# iqn_ail register map
Vendor: Texas Instruments
Registers are 32-bit, read-only, no defined reset value unless marked. A register's access mark holds for its fields unless they carry their own. Offsets are as the file gives them; [hi:lo] are bit positions.

## IQN_AIL (part 5 of 5)
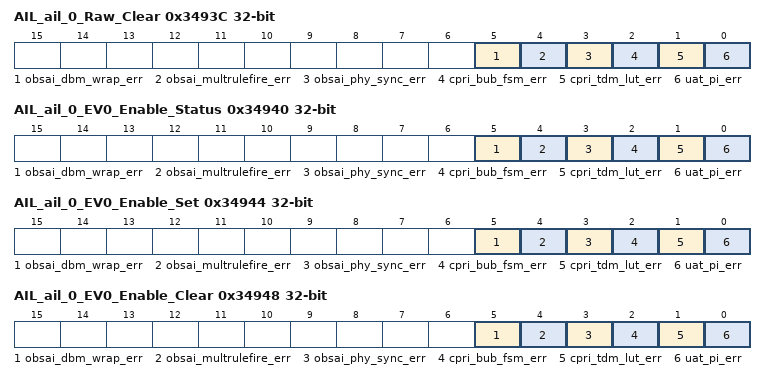
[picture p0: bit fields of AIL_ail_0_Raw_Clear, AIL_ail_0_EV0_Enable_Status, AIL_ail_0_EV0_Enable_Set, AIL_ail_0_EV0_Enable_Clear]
0x3493C AIL_ail_0_Raw_Clear wo — (1 of 1, stride 0)
  [5] obsai_dbm_wrap_err — Clears the corresponding bit in the raw_status register when set. Write only, self-clears.
  [4] obsai_multrulefire_err — Clears the corresponding bit in the raw_status register when set. Write only, self-clears.
  [3] obsai_phy_sync_err — Clears the corresponding bit in the raw_status register when set. Write only, self-clears.
  [2] cpri_bub_fsm_err — Clears the corresponding bit in the raw_status register when set. Write only, self-clears.
  [1] cpri_tdm_lut_err — Clears the corresponding bit in the raw_status register when set. Write only, self-clears.
  [0] uat_pi_err — Clears the corresponding bit in the raw_status register when set. Write only, self-clears.
0x34940 AIL_ail_0_EV0_Enable_Status — (1 of 1, stride 0)
  [5] obsai_dbm_wrap_err — When set allows the corresponding bit in the raw_status register to generate the intr_sts interrupt. Read only.
  [4] obsai_multrulefire_err — When set allows the corresponding bit in the raw_status register to generate the intr_sts interrupt. Read only.
  [3] obsai_phy_sync_err — When set allows the corresponding bit in the raw_status register to generate the intr_sts interrupt. Read only.
  [2] cpri_bub_fsm_err — When set allows the corresponding bit in the raw_status register to generate the intr_sts interrupt. Read only.
  [1] cpri_tdm_lut_err — When set allows the corresponding bit in the raw_status register to generate the intr_sts interrupt. Read only.
  [0] uat_pi_err — When set allows the corresponding bit in the raw_status register to generate the intr_sts interrupt. Read only.
0x34944 AIL_ail_0_EV0_Enable_Set wo — (1 of 1, stride 0)
  [5] obsai_dbm_wrap_err — Sets the corresponding bit in the enable register when set. Write only, self-clears.
  [4] obsai_multrulefire_err — Sets the corresponding bit in the enable register when set. Write only, self-clears.
  [3] obsai_phy_sync_err — Sets the corresponding bit in the enable register when set. Write only, self-clears.
  [2] cpri_bub_fsm_err — Sets the corresponding bit in the enable register when set. Write only, self-clears.
  [1] cpri_tdm_lut_err — Sets the corresponding bit in the enable register when set. Write only, self-clears.
  [0] uat_pi_err — Sets the corresponding bit in the enable register when set. Write only, self-clears.
0x34948 AIL_ail_0_EV0_Enable_Clear wo — (1 of 1, stride 0)
  [5] obsai_dbm_wrap_err — Clears the corresponding bit in the enable register when set. Write only, self-clears.
  [4] obsai_multrulefire_err — Clears the corresponding bit in the enable register when set. Write only, self-clears.
  [3] obsai_phy_sync_err — Clears the corresponding bit in the enable register when set. Write only, self-clears.
  [2] cpri_bub_fsm_err — Clears the corresponding bit in the enable register when set. Write only, self-clears.
  [1] cpri_tdm_lut_err — Clears the corresponding bit in the enable register when set. Write only, self-clears.
  [0] uat_pi_err — Clears the corresponding bit in the enable register when set. Write only, self-clears.
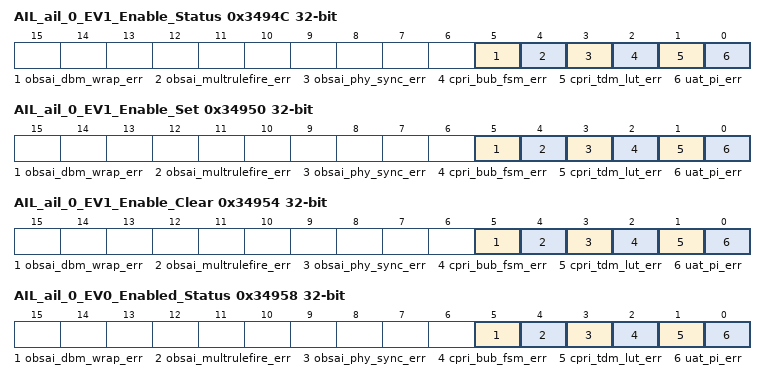
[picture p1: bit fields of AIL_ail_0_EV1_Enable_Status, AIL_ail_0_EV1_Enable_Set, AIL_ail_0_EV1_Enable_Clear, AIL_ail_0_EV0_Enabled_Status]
0x3494C AIL_ail_0_EV1_Enable_Status — (1 of 1, stride 0)
  [5] obsai_dbm_wrap_err — When set allows the corresponding bit in the raw_status register to generate the intr1_sts interrupt. Read only.
  [4] obsai_multrulefire_err — When set allows the corresponding bit in the raw_status register to generate the intr1_sts interrupt. Read only.
  [3] obsai_phy_sync_err — When set allows the corresponding bit in the raw_status register to generate the intr1_sts interrupt. Read only.
  [2] cpri_bub_fsm_err — When set allows the corresponding bit in the raw_status register to generate the intr1_sts interrupt. Read only.
  [1] cpri_tdm_lut_err — When set allows the corresponding bit in the raw_status register to generate the intr1_sts interrupt. Read only.
  [0] uat_pi_err — When set allows the corresponding bit in the raw_status register to generate the intr1_sts interrupt. Read only.
0x34950 AIL_ail_0_EV1_Enable_Set wo — (1 of 1, stride 0)
  [5] obsai_dbm_wrap_err — Sets the corresponding bit in the intr1_status register when set. Write only, self-clears.
  [4] obsai_multrulefire_err — Sets the corresponding bit in the intr1_status register when set. Write only, self-clears.
  [3] obsai_phy_sync_err — Sets the corresponding bit in the intr1_status register when set. Write only, self-clears.
  [2] cpri_bub_fsm_err — Sets the corresponding bit in the intr1_status register when set. Write only, self-clears.
  [1] cpri_tdm_lut_err — Sets the corresponding bit in the intr1_status register when set. Write only, self-clears.
  [0] uat_pi_err — Sets the corresponding bit in the intr1_status register when set. Write only, self-clears.
0x34954 AIL_ail_0_EV1_Enable_Clear wo — (1 of 1, stride 0)
  [5] obsai_dbm_wrap_err — Clears the corresponding bit in the intr1_status register when set. Write only, self-clears.
  [4] obsai_multrulefire_err — Clears the corresponding bit in the intr1_status register when set. Write only, self-clears.
  [3] obsai_phy_sync_err — Clears the corresponding bit in the intr1_status register when set. Write only, self-clears.
  [2] cpri_bub_fsm_err — Clears the corresponding bit in the intr1_status register when set. Write only, self-clears.
  [1] cpri_tdm_lut_err — Clears the corresponding bit in the intr1_status register when set. Write only, self-clears.
  [0] uat_pi_err — Clears the corresponding bit in the intr1_status register when set. Write only, self-clears.
0x34958 AIL_ail_0_EV0_Enabled_Status — (1 of 1, stride 0)
  [5] obsai_dbm_wrap_err — AND-ed raw_status bits with the corresponding bit in the enable_status register. Read only.
  [4] obsai_multrulefire_err — AND-ed raw_status bits with the corresponding bit in the enable_status register. Read only.
  [3] obsai_phy_sync_err — AND-ed raw_status bits with the corresponding bit in the enable_status register. Read only.
  [2] cpri_bub_fsm_err — AND-ed raw_status bits with the corresponding bit in the enable_status register. Read only.
  [1] cpri_tdm_lut_err — AND-ed raw_status bits with the corresponding bit in the enable_status register. Read only.
  [0] uat_pi_err — AND-ed raw_status bits with the corresponding bit in the enable_status register. Read only.
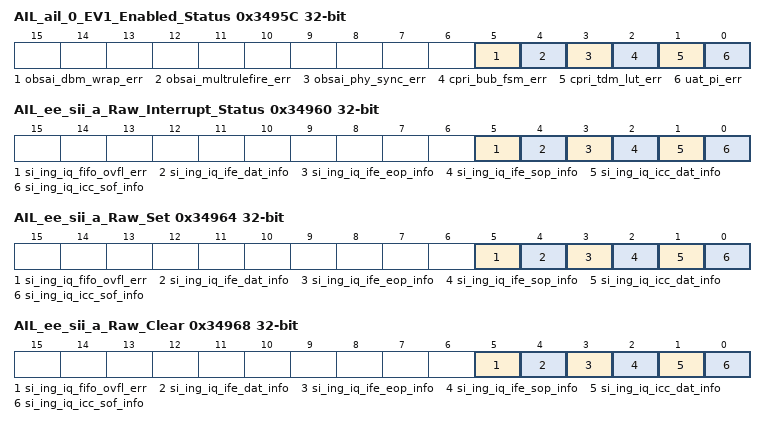
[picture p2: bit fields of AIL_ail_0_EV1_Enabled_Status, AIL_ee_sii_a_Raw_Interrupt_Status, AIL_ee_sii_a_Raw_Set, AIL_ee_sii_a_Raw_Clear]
0x3495C AIL_ail_0_EV1_Enabled_Status — (1 of 1, stride 0)
  [5] obsai_dbm_wrap_err — AND-ed raw_status bits with the corresponding bit in the intr1_status register. Read only.
  [4] obsai_multrulefire_err — AND-ed raw_status bits with the corresponding bit in the intr1_status register. Read only.
  [3] obsai_phy_sync_err — AND-ed raw_status bits with the corresponding bit in the intr1_status register. Read only.
  [2] cpri_bub_fsm_err — AND-ed raw_status bits with the corresponding bit in the intr1_status register. Read only.
  [1] cpri_tdm_lut_err — AND-ed raw_status bits with the corresponding bit in the intr1_status register. Read only.
  [0] uat_pi_err — AND-ed raw_status bits with the corresponding bit in the intr1_status register. Read only.
0x34960 AIL_ee_sii_a_Raw_Interrupt_Status — (1 of 1, stride 0)
  [5] si_ing_iq_fifo_ovfl_err — SI Ingress IQ FIFO overflow error
  [4] si_ing_iq_ife_dat_info — SI Ingress IQ IFE transmitted valid data phase
  [3] si_ing_iq_ife_eop_info — SI Ingress IQ IFE transmitted EOP
  [2] si_ing_iq_ife_sop_info — SI Ingress IQ IFE transmitted SOP
  [1] si_ing_iq_icc_dat_info — SI Ingress IQ ICC data transfer received
  [0] si_ing_iq_icc_sof_info — SI Ingress IQ ICC Start of Frame received
0x34964 AIL_ee_sii_a_Raw_Set wo — (1 of 1, stride 0)
  [5] si_ing_iq_fifo_ovfl_err — Sets the corresponding bit in the raw_status register when set. Write only, self-clears.
  [4] si_ing_iq_ife_dat_info — Sets the corresponding bit in the raw_status register when set. Write only, self-clears.
  [3] si_ing_iq_ife_eop_info — Sets the corresponding bit in the raw_status register when set. Write only, self-clears.
  [2] si_ing_iq_ife_sop_info — Sets the corresponding bit in the raw_status register when set. Write only, self-clears.
  [1] si_ing_iq_icc_dat_info — Sets the corresponding bit in the raw_status register when set. Write only, self-clears.
  [0] si_ing_iq_icc_sof_info — Sets the corresponding bit in the raw_status register when set. Write only, self-clears.
0x34968 AIL_ee_sii_a_Raw_Clear wo — (1 of 1, stride 0)
  [5] si_ing_iq_fifo_ovfl_err — Clears the corresponding bit in the raw_status register when set. Write only, self-clears.
  [4] si_ing_iq_ife_dat_info — Clears the corresponding bit in the raw_status register when set. Write only, self-clears.
  [3] si_ing_iq_ife_eop_info — Clears the corresponding bit in the raw_status register when set. Write only, self-clears.
  [2] si_ing_iq_ife_sop_info — Clears the corresponding bit in the raw_status register when set. Write only, self-clears.
  [1] si_ing_iq_icc_dat_info — Clears the corresponding bit in the raw_status register when set. Write only, self-clears.
  [0] si_ing_iq_icc_sof_info — Clears the corresponding bit in the raw_status register when set. Write only, self-clears.
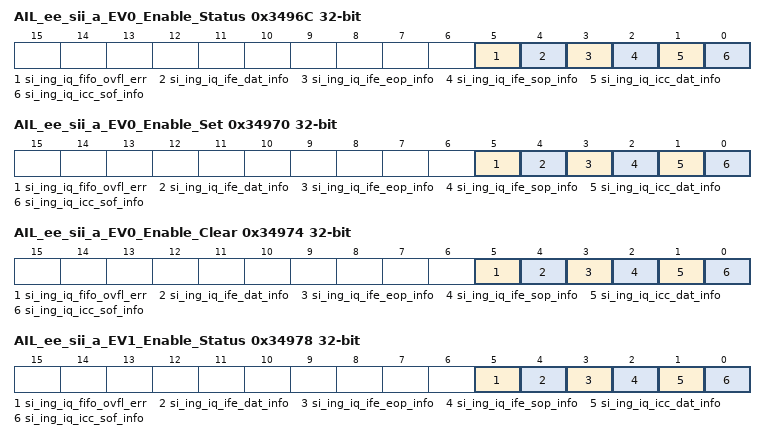
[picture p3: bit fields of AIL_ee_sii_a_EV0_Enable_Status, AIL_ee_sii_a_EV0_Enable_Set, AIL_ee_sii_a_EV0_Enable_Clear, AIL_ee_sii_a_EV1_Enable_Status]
0x3496C AIL_ee_sii_a_EV0_Enable_Status — (1 of 1, stride 0)
  [5] si_ing_iq_fifo_ovfl_err — When set allows the corresponding bit in the raw_status register to generate the intr_sts interrupt. Read only.
  [4] si_ing_iq_ife_dat_info — When set allows the corresponding bit in the raw_status register to generate the intr_sts interrupt. Read only.
  [3] si_ing_iq_ife_eop_info — When set allows the corresponding bit in the raw_status register to generate the intr_sts interrupt. Read only.
  [2] si_ing_iq_ife_sop_info — When set allows the corresponding bit in the raw_status register to generate the intr_sts interrupt. Read only.
  [1] si_ing_iq_icc_dat_info — When set allows the corresponding bit in the raw_status register to generate the intr_sts interrupt. Read only.
  [0] si_ing_iq_icc_sof_info — When set allows the corresponding bit in the raw_status register to generate the intr_sts interrupt. Read only.
0x34970 AIL_ee_sii_a_EV0_Enable_Set wo — (1 of 1, stride 0)
  [5] si_ing_iq_fifo_ovfl_err — Sets the corresponding bit in the enable register when set. Write only, self-clears.
  [4] si_ing_iq_ife_dat_info — Sets the corresponding bit in the enable register when set. Write only, self-clears.
  [3] si_ing_iq_ife_eop_info — Sets the corresponding bit in the enable register when set. Write only, self-clears.
  [2] si_ing_iq_ife_sop_info — Sets the corresponding bit in the enable register when set. Write only, self-clears.
  [1] si_ing_iq_icc_dat_info — Sets the corresponding bit in the enable register when set. Write only, self-clears.
  [0] si_ing_iq_icc_sof_info — Sets the corresponding bit in the enable register when set. Write only, self-clears.
0x34974 AIL_ee_sii_a_EV0_Enable_Clear wo — (1 of 1, stride 0)
  [5] si_ing_iq_fifo_ovfl_err — Clears the corresponding bit in the enable register when set. Write only, self-clears.
  [4] si_ing_iq_ife_dat_info — Clears the corresponding bit in the enable register when set. Write only, self-clears.
  [3] si_ing_iq_ife_eop_info — Clears the corresponding bit in the enable register when set. Write only, self-clears.
  [2] si_ing_iq_ife_sop_info — Clears the corresponding bit in the enable register when set. Write only, self-clears.
  [1] si_ing_iq_icc_dat_info — Clears the corresponding bit in the enable register when set. Write only, self-clears.
  [0] si_ing_iq_icc_sof_info — Clears the corresponding bit in the enable register when set. Write only, self-clears.
0x34978 AIL_ee_sii_a_EV1_Enable_Status — (1 of 1, stride 0)
  [5] si_ing_iq_fifo_ovfl_err — When set allows the corresponding bit in the raw_status register to generate the intr1_sts interrupt. Read only.
  [4] si_ing_iq_ife_dat_info — When set allows the corresponding bit in the raw_status register to generate the intr1_sts interrupt. Read only.
  [3] si_ing_iq_ife_eop_info — When set allows the corresponding bit in the raw_status register to generate the intr1_sts interrupt. Read only.
  [2] si_ing_iq_ife_sop_info — When set allows the corresponding bit in the raw_status register to generate the intr1_sts interrupt. Read only.
  [1] si_ing_iq_icc_dat_info — When set allows the corresponding bit in the raw_status register to generate the intr1_sts interrupt. Read only.
  [0] si_ing_iq_icc_sof_info — When set allows the corresponding bit in the raw_status register to generate the intr1_sts interrupt. Read only.
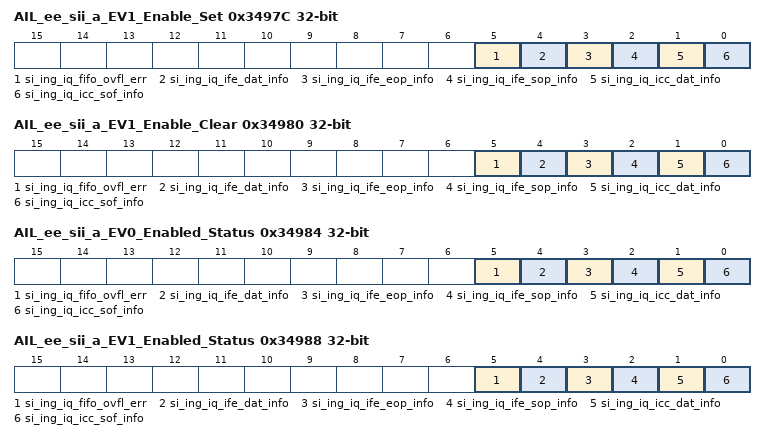
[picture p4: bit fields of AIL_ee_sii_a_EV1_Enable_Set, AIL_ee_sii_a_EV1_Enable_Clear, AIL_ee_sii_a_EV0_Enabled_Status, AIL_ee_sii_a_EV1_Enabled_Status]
0x3497C AIL_ee_sii_a_EV1_Enable_Set wo — (1 of 1, stride 0)
  [5] si_ing_iq_fifo_ovfl_err — Sets the corresponding bit in the intr1_status register when set. Write only, self-clears.
  [4] si_ing_iq_ife_dat_info — Sets the corresponding bit in the intr1_status register when set. Write only, self-clears.
  [3] si_ing_iq_ife_eop_info — Sets the corresponding bit in the intr1_status register when set. Write only, self-clears.
  [2] si_ing_iq_ife_sop_info — Sets the corresponding bit in the intr1_status register when set. Write only, self-clears.
  [1] si_ing_iq_icc_dat_info — Sets the corresponding bit in the intr1_status register when set. Write only, self-clears.
  [0] si_ing_iq_icc_sof_info — Sets the corresponding bit in the intr1_status register when set. Write only, self-clears.
0x34980 AIL_ee_sii_a_EV1_Enable_Clear wo — (1 of 1, stride 0)
  [5] si_ing_iq_fifo_ovfl_err — Clears the corresponding bit in the intr1_status register when set. Write only, self-clears.
  [4] si_ing_iq_ife_dat_info — Clears the corresponding bit in the intr1_status register when set. Write only, self-clears.
  [3] si_ing_iq_ife_eop_info — Clears the corresponding bit in the intr1_status register when set. Write only, self-clears.
  [2] si_ing_iq_ife_sop_info — Clears the corresponding bit in the intr1_status register when set. Write only, self-clears.
  [1] si_ing_iq_icc_dat_info — Clears the corresponding bit in the intr1_status register when set. Write only, self-clears.
  [0] si_ing_iq_icc_sof_info — Clears the corresponding bit in the intr1_status register when set. Write only, self-clears.
0x34984 AIL_ee_sii_a_EV0_Enabled_Status — (1 of 1, stride 0)
  [5] si_ing_iq_fifo_ovfl_err — AND-ed raw_status bits with the corresponding bit in the enable_status register. Read only.
  [4] si_ing_iq_ife_dat_info — AND-ed raw_status bits with the corresponding bit in the enable_status register. Read only.
  [3] si_ing_iq_ife_eop_info — AND-ed raw_status bits with the corresponding bit in the enable_status register. Read only.
  [2] si_ing_iq_ife_sop_info — AND-ed raw_status bits with the corresponding bit in the enable_status register. Read only.
  [1] si_ing_iq_icc_dat_info — AND-ed raw_status bits with the corresponding bit in the enable_status register. Read only.
  [0] si_ing_iq_icc_sof_info — AND-ed raw_status bits with the corresponding bit in the enable_status register. Read only.
0x34988 AIL_ee_sii_a_EV1_Enabled_Status — (1 of 1, stride 0)
  [5] si_ing_iq_fifo_ovfl_err — AND-ed raw_status bits with the corresponding bit in the intr1_status register. Read only.
  [4] si_ing_iq_ife_dat_info — AND-ed raw_status bits with the corresponding bit in the intr1_status register. Read only.
  [3] si_ing_iq_ife_eop_info — AND-ed raw_status bits with the corresponding bit in the intr1_status register. Read only.
  [2] si_ing_iq_ife_sop_info — AND-ed raw_status bits with the corresponding bit in the intr1_status register. Read only.
  [1] si_ing_iq_icc_dat_info — AND-ed raw_status bits with the corresponding bit in the intr1_status register. Read only.
  [0] si_ing_iq_icc_sof_info — AND-ed raw_status bits with the corresponding bit in the intr1_status register. Read only.
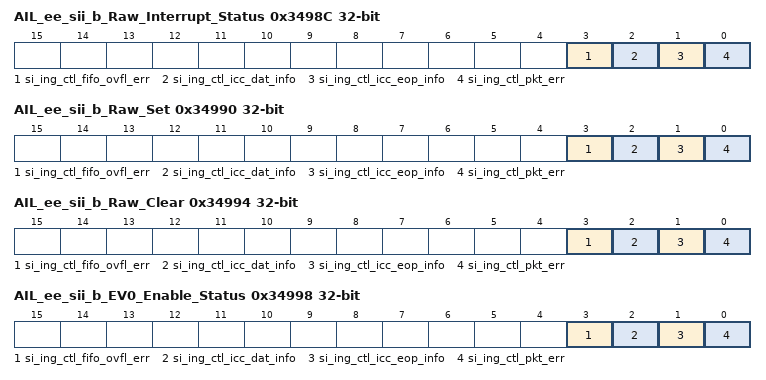
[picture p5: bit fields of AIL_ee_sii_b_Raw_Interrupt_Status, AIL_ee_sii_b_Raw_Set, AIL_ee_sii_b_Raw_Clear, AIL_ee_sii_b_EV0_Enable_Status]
0x3498C AIL_ee_sii_b_Raw_Interrupt_Status — (1 of 1, stride 0)
  [3] si_ing_ctl_fifo_ovfl_err — SI Ingress CTL FIFO overflow error
  [2] si_ing_ctl_icc_dat_info — SI Ingress CTL received valid data phase from ICC
  [1] si_ing_ctl_icc_eop_info — SI Ingress CTL received EOP from ICC
  [0] si_ing_ctl_pkt_err — SI Ingress CTL Packet error occurred
0x34990 AIL_ee_sii_b_Raw_Set wo — (1 of 1, stride 0)
  [3] si_ing_ctl_fifo_ovfl_err — Sets the corresponding bit in the raw_status register when set. Write only, self-clears.
  [2] si_ing_ctl_icc_dat_info — Sets the corresponding bit in the raw_status register when set. Write only, self-clears.
  [1] si_ing_ctl_icc_eop_info — Sets the corresponding bit in the raw_status register when set. Write only, self-clears.
  [0] si_ing_ctl_pkt_err — Sets the corresponding bit in the raw_status register when set. Write only, self-clears.
0x34994 AIL_ee_sii_b_Raw_Clear wo — (1 of 1, stride 0)
  [3] si_ing_ctl_fifo_ovfl_err — Clears the corresponding bit in the raw_status register when set. Write only, self-clears.
  [2] si_ing_ctl_icc_dat_info — Clears the corresponding bit in the raw_status register when set. Write only, self-clears.
  [1] si_ing_ctl_icc_eop_info — Clears the corresponding bit in the raw_status register when set. Write only, self-clears.
  [0] si_ing_ctl_pkt_err — Clears the corresponding bit in the raw_status register when set. Write only, self-clears.
0x34998 AIL_ee_sii_b_EV0_Enable_Status — (1 of 1, stride 0)
  [3] si_ing_ctl_fifo_ovfl_err — When set allows the corresponding bit in the raw_status register to generate the intr_sts interrupt. Read only.
  [2] si_ing_ctl_icc_dat_info — When set allows the corresponding bit in the raw_status register to generate the intr_sts interrupt. Read only.
  [1] si_ing_ctl_icc_eop_info — When set allows the corresponding bit in the raw_status register to generate the intr_sts interrupt. Read only.
  [0] si_ing_ctl_pkt_err — When set allows the corresponding bit in the raw_status register to generate the intr_sts interrupt. Read only.
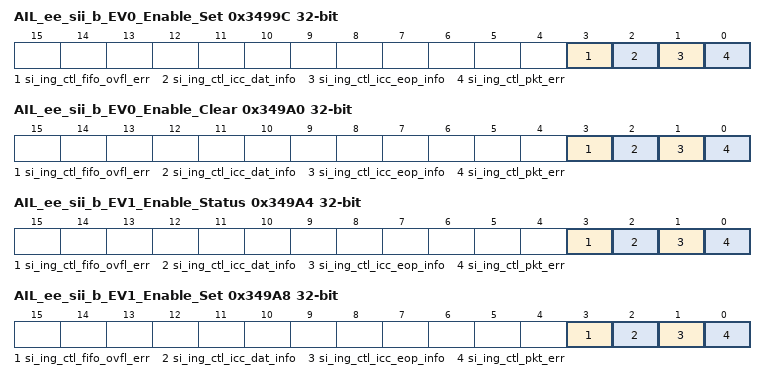
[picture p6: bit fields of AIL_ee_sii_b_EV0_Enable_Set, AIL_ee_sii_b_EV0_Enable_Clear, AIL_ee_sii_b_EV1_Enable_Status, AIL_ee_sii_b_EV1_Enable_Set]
0x3499C AIL_ee_sii_b_EV0_Enable_Set wo — (1 of 1, stride 0)
  [3] si_ing_ctl_fifo_ovfl_err — Sets the corresponding bit in the enable register when set. Write only, self-clears.
  [2] si_ing_ctl_icc_dat_info — Sets the corresponding bit in the enable register when set. Write only, self-clears.
  [1] si_ing_ctl_icc_eop_info — Sets the corresponding bit in the enable register when set. Write only, self-clears.
  [0] si_ing_ctl_pkt_err — Sets the corresponding bit in the enable register when set. Write only, self-clears.
0x349A0 AIL_ee_sii_b_EV0_Enable_Clear wo — (1 of 1, stride 0)
  [3] si_ing_ctl_fifo_ovfl_err — Clears the corresponding bit in the enable register when set. Write only, self-clears.
  [2] si_ing_ctl_icc_dat_info — Clears the corresponding bit in the enable register when set. Write only, self-clears.
  [1] si_ing_ctl_icc_eop_info — Clears the corresponding bit in the enable register when set. Write only, self-clears.
  [0] si_ing_ctl_pkt_err — Clears the corresponding bit in the enable register when set. Write only, self-clears.
0x349A4 AIL_ee_sii_b_EV1_Enable_Status — (1 of 1, stride 0)
  [3] si_ing_ctl_fifo_ovfl_err — When set allows the corresponding bit in the raw_status register to generate the intr1_sts interrupt. Read only.
  [2] si_ing_ctl_icc_dat_info — When set allows the corresponding bit in the raw_status register to generate the intr1_sts interrupt. Read only.
  [1] si_ing_ctl_icc_eop_info — When set allows the corresponding bit in the raw_status register to generate the intr1_sts interrupt. Read only.
  [0] si_ing_ctl_pkt_err — When set allows the corresponding bit in the raw_status register to generate the intr1_sts interrupt. Read only.
0x349A8 AIL_ee_sii_b_EV1_Enable_Set wo — (1 of 1, stride 0)
  [3] si_ing_ctl_fifo_ovfl_err — Sets the corresponding bit in the intr1_status register when set. Write only, self-clears.
  [2] si_ing_ctl_icc_dat_info — Sets the corresponding bit in the intr1_status register when set. Write only, self-clears.
  [1] si_ing_ctl_icc_eop_info — Sets the corresponding bit in the intr1_status register when set. Write only, self-clears.
  [0] si_ing_ctl_pkt_err — Sets the corresponding bit in the intr1_status register when set. Write only, self-clears.
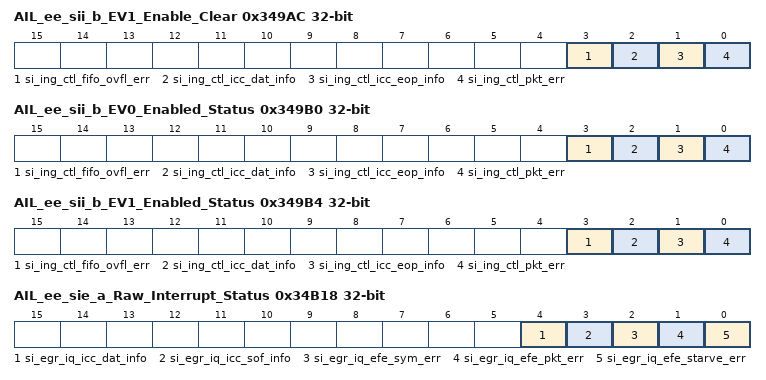
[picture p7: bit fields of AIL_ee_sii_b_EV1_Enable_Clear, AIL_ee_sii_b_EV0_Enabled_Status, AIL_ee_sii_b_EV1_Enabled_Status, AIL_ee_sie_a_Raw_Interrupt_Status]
0x349AC AIL_ee_sii_b_EV1_Enable_Clear wo — (1 of 1, stride 0)
  [3] si_ing_ctl_fifo_ovfl_err — Clears the corresponding bit in the intr1_status register when set. Write only, self-clears.
  [2] si_ing_ctl_icc_dat_info — Clears the corresponding bit in the intr1_status register when set. Write only, self-clears.
  [1] si_ing_ctl_icc_eop_info — Clears the corresponding bit in the intr1_status register when set. Write only, self-clears.
  [0] si_ing_ctl_pkt_err — Clears the corresponding bit in the intr1_status register when set. Write only, self-clears.
0x349B0 AIL_ee_sii_b_EV0_Enabled_Status — (1 of 1, stride 0)
  [3] si_ing_ctl_fifo_ovfl_err — AND-ed raw_status bits with the corresponding bit in the enable_status register. Read only.
  [2] si_ing_ctl_icc_dat_info — AND-ed raw_status bits with the corresponding bit in the enable_status register. Read only.
  [1] si_ing_ctl_icc_eop_info — AND-ed raw_status bits with the corresponding bit in the enable_status register. Read only.
  [0] si_ing_ctl_pkt_err — AND-ed raw_status bits with the corresponding bit in the enable_status register. Read only.
0x349B4 AIL_ee_sii_b_EV1_Enabled_Status — (1 of 1, stride 0)
  [3] si_ing_ctl_fifo_ovfl_err — AND-ed raw_status bits with the corresponding bit in the intr1_status register. Read only.
  [2] si_ing_ctl_icc_dat_info — AND-ed raw_status bits with the corresponding bit in the intr1_status register. Read only.
  [1] si_ing_ctl_icc_eop_info — AND-ed raw_status bits with the corresponding bit in the intr1_status register. Read only.
  [0] si_ing_ctl_pkt_err — AND-ed raw_status bits with the corresponding bit in the intr1_status register. Read only.
0x349B8 AIL_ee_sii_c_0_Raw_Interrupt_Status — (1 of 1, stride 0)
  [31:0] si_ing_iq_sof_err — SI Ingress IQ per channel Start of Frame alignment error
0x349BC AIL_ee_sii_c_0_Raw_Set wo — (1 of 1, stride 0)
  [31:0] si_ing_iq_sof_err — Sets the corresponding bit in the raw_status register when set. Write only, self-clears.
0x349C0 AIL_ee_sii_c_0_Raw_Clear wo — (1 of 1, stride 0)
  [31:0] si_ing_iq_sof_err — Clears the corresponding bit in the raw_status register when set. Write only, self-clears.
0x349C4 AIL_ee_sii_c_0_EV0_Enable_Status — (1 of 1, stride 0)
  [31:0] si_ing_iq_sof_err — When set allows the corresponding bit in the raw_status register to generate the intr_sts interrupt. Read only.
0x349C8 AIL_ee_sii_c_0_EV0_Enable_Set wo — (1 of 1, stride 0)
  [31:0] si_ing_iq_sof_err — Sets the corresponding bit in the enable register when set. Write only, self-clears.
0x349CC AIL_ee_sii_c_0_EV0_Enable_Clear wo — (1 of 1, stride 0)
  [31:0] si_ing_iq_sof_err — Clears the corresponding bit in the enable register when set. Write only, self-clears.
0x349D0 AIL_ee_sii_c_0_EV1_Enable_Status — (1 of 1, stride 0)
  [31:0] si_ing_iq_sof_err — When set allows the corresponding bit in the raw_status register to generate the intr1_sts interrupt. Read only.
0x349D4 AIL_ee_sii_c_0_EV1_Enable_Set wo — (1 of 1, stride 0)
  [31:0] si_ing_iq_sof_err — Sets the corresponding bit in the intr1_status register when set. Write only, self-clears.
0x349D8 AIL_ee_sii_c_0_EV1_Enable_Clear wo — (1 of 1, stride 0)
  [31:0] si_ing_iq_sof_err — Clears the corresponding bit in the intr1_status register when set. Write only, self-clears.
0x349DC AIL_ee_sii_c_0_EV0_Enabled_Status — (1 of 1, stride 0)
  [31:0] si_ing_iq_sof_err — AND-ed raw_status bits with the corresponding bit in the enable_status register. Read only.
0x349E0 AIL_ee_sii_c_0_EV1_Enabled_Status — (1 of 1, stride 0)
  [31:0] si_ing_iq_sof_err — AND-ed raw_status bits with the corresponding bit in the intr1_status register. Read only.
0x349E4 AIL_ee_sii_c_1_Raw_Interrupt_Status — (1 of 1, stride 0)
  [31:0] si_ing_iq_sof_err_64_32 — SI Ingress IQ per channel Start of Frame alignment error
0x349E8 AIL_ee_sii_c_1_Raw_Set wo — (1 of 1, stride 0)
  [31:0] si_ing_iq_sof_err_64_32 — Sets the corresponding bit in the raw_status register when set. Write only, self-clears.
0x349EC AIL_ee_sii_c_1_Raw_Clear wo — (1 of 1, stride 0)
  [31:0] si_ing_iq_sof_err_64_32 — Clears the corresponding bit in the raw_status register when set. Write only, self-clears.
0x349F0 AIL_ee_sii_c_1_EV0_Enable_Status — (1 of 1, stride 0)
  [31:0] si_ing_iq_sof_err_64_32 — When set allows the corresponding bit in the raw_status register to generate the intr_sts interrupt. Read only.
0x349F4 AIL_ee_sii_c_1_EV0_Enable_Set wo — (1 of 1, stride 0)
  [31:0] si_ing_iq_sof_err_64_32 — Sets the corresponding bit in the enable register when set. Write only, self-clears.
0x349F8 AIL_ee_sii_c_1_EV0_Enable_Clear wo — (1 of 1, stride 0)
  [31:0] si_ing_iq_sof_err_64_32 — Clears the corresponding bit in the enable register when set. Write only, self-clears.
0x349FC AIL_ee_sii_c_1_EV1_Enable_Status — (1 of 1, stride 0)
  [31:0] si_ing_iq_sof_err_64_32 — When set allows the corresponding bit in the raw_status register to generate the intr1_sts interrupt. Read only.
0x34A00 AIL_ee_sii_c_1_EV1_Enable_Set wo — (1 of 1, stride 0)
  [31:0] si_ing_iq_sof_err_64_32 — Sets the corresponding bit in the intr1_status register when set. Write only, self-clears.
0x34A04 AIL_ee_sii_c_1_EV1_Enable_Clear wo — (1 of 1, stride 0)
  [31:0] si_ing_iq_sof_err_64_32 — Clears the corresponding bit in the intr1_status register when set. Write only, self-clears.
0x34A08 AIL_ee_sii_c_1_EV0_Enabled_Status — (1 of 1, stride 0)
  [31:0] si_ing_iq_sof_err_64_32 — AND-ed raw_status bits with the corresponding bit in the enable_status register. Read only.
0x34A0C AIL_ee_sii_c_1_EV1_Enabled_Status — (1 of 1, stride 0)
  [31:0] si_ing_iq_sof_err_64_32 — AND-ed raw_status bits with the corresponding bit in the intr1_status register. Read only.
0x34A68 AIL_ee_sii_d_Raw_Interrupt_Status — (1 of 1, stride 0)
  [3:0] si_ing_ctl_icc_sop_info — SI Ingress CTL per channel SOP received from ICC
0x34A6C AIL_ee_sii_d_Raw_Set wo — (1 of 1, stride 0)
  [3:0] si_ing_ctl_icc_sop_info — Sets the corresponding bit in the raw_status register when set. Write only, self-clears.
0x34A70 AIL_ee_sii_d_Raw_Clear wo — (1 of 1, stride 0)
  [3:0] si_ing_ctl_icc_sop_info — Clears the corresponding bit in the raw_status register when set. Write only, self-clears.
0x34A74 AIL_ee_sii_d_EV0_Enable_Status — (1 of 1, stride 0)
  [3:0] si_ing_ctl_icc_sop_info — When set allows the corresponding bit in the raw_status register to generate the intr_sts interrupt. Read only.
0x34A78 AIL_ee_sii_d_EV0_Enable_Set wo — (1 of 1, stride 0)
  [3:0] si_ing_ctl_icc_sop_info — Sets the corresponding bit in the enable register when set. Write only, self-clears.
0x34A7C AIL_ee_sii_d_EV0_Enable_Clear wo — (1 of 1, stride 0)
  [3:0] si_ing_ctl_icc_sop_info — Clears the corresponding bit in the enable register when set. Write only, self-clears.
0x34A80 AIL_ee_sii_d_EV1_Enable_Status — (1 of 1, stride 0)
  [3:0] si_ing_ctl_icc_sop_info — When set allows the corresponding bit in the raw_status register to generate the intr1_sts interrupt. Read only.
0x34A84 AIL_ee_sii_d_EV1_Enable_Set wo — (1 of 1, stride 0)
  [3:0] si_ing_ctl_icc_sop_info — Sets the corresponding bit in the intr1_status register when set. Write only, self-clears.
0x34A88 AIL_ee_sii_d_EV1_Enable_Clear wo — (1 of 1, stride 0)
  [3:0] si_ing_ctl_icc_sop_info — Clears the corresponding bit in the intr1_status register when set. Write only, self-clears.
0x34A8C AIL_ee_sii_d_EV0_Enabled_Status — (1 of 1, stride 0)
  [3:0] si_ing_ctl_icc_sop_info — AND-ed raw_status bits with the corresponding bit in the enable_status register. Read only.
0x34A90 AIL_ee_sii_d_EV1_Enabled_Status — (1 of 1, stride 0)
  [3:0] si_ing_ctl_icc_sop_info — AND-ed raw_status bits with the corresponding bit in the intr1_status register. Read only.
0x34B18 AIL_ee_sie_a_Raw_Interrupt_Status — (1 of 1, stride 0)
  [4] si_egr_iq_icc_dat_info — SI Egress IQ transmitted data to ICC
  [3] si_egr_iq_icc_sof_info — SI Egress IQ transmitted Start of Frame to ICC
  [2] si_egr_iq_efe_sym_err — SI Egress IQ EFE symbol number error. (Packet boundary errors due to a missing, early, or late SOP disable the reporting of any symbol errors since the symbol number is only valid for SOPs)
  [1] si_egr_iq_efe_pkt_err — SI Egress IQ EFE packet boundary error
  [0] si_egr_iq_efe_starve_err — SI Egress IQ EFE data starvation error
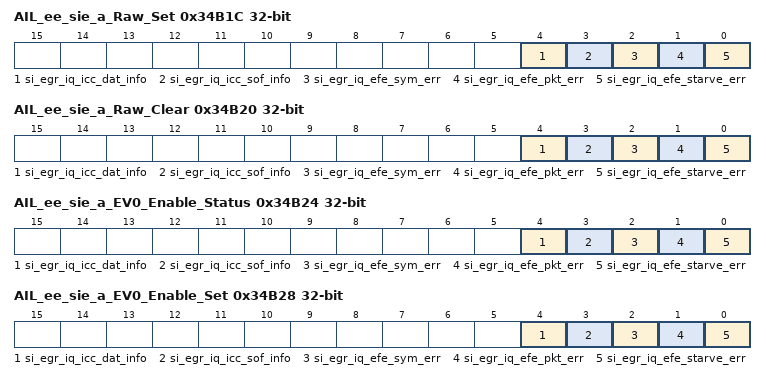
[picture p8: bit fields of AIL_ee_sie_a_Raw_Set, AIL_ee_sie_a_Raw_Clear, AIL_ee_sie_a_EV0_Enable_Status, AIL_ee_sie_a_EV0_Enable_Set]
0x34B1C AIL_ee_sie_a_Raw_Set wo — (1 of 1, stride 0)
  [4] si_egr_iq_icc_dat_info — Sets the corresponding bit in the raw_status register when set. Write only, self-clears.
  [3] si_egr_iq_icc_sof_info — Sets the corresponding bit in the raw_status register when set. Write only, self-clears.
  [2] si_egr_iq_efe_sym_err — Sets the corresponding bit in the raw_status register when set. Write only, self-clears.
  [1] si_egr_iq_efe_pkt_err — Sets the corresponding bit in the raw_status register when set. Write only, self-clears.
  [0] si_egr_iq_efe_starve_err — Sets the corresponding bit in the raw_status register when set. Write only, self-clears.
0x34B20 AIL_ee_sie_a_Raw_Clear wo — (1 of 1, stride 0)
  [4] si_egr_iq_icc_dat_info — Clears the corresponding bit in the raw_status register when set. Write only, self-clears.
  [3] si_egr_iq_icc_sof_info — Clears the corresponding bit in the raw_status register when set. Write only, self-clears.
  [2] si_egr_iq_efe_sym_err — Clears the corresponding bit in the raw_status register when set. Write only, self-clears.
  [1] si_egr_iq_efe_pkt_err — Clears the corresponding bit in the raw_status register when set. Write only, self-clears.
  [0] si_egr_iq_efe_starve_err — Clears the corresponding bit in the raw_status register when set. Write only, self-clears.
0x34B24 AIL_ee_sie_a_EV0_Enable_Status — (1 of 1, stride 0)
  [4] si_egr_iq_icc_dat_info — When set allows the corresponding bit in the raw_status register to generate the intr_sts interrupt. Read only.
  [3] si_egr_iq_icc_sof_info — When set allows the corresponding bit in the raw_status register to generate the intr_sts interrupt. Read only.
  [2] si_egr_iq_efe_sym_err — When set allows the corresponding bit in the raw_status register to generate the intr_sts interrupt. Read only.
  [1] si_egr_iq_efe_pkt_err — When set allows the corresponding bit in the raw_status register to generate the intr_sts interrupt. Read only.
  [0] si_egr_iq_efe_starve_err — When set allows the corresponding bit in the raw_status register to generate the intr_sts interrupt. Read only.
0x34B28 AIL_ee_sie_a_EV0_Enable_Set wo — (1 of 1, stride 0)
  [4] si_egr_iq_icc_dat_info — Sets the corresponding bit in the enable register when set. Write only, self-clears.
  [3] si_egr_iq_icc_sof_info — Sets the corresponding bit in the enable register when set. Write only, self-clears.
  [2] si_egr_iq_efe_sym_err — Sets the corresponding bit in the enable register when set. Write only, self-clears.
  [1] si_egr_iq_efe_pkt_err — Sets the corresponding bit in the enable register when set. Write only, self-clears.
  [0] si_egr_iq_efe_starve_err — Sets the corresponding bit in the enable register when set. Write only, self-clears.
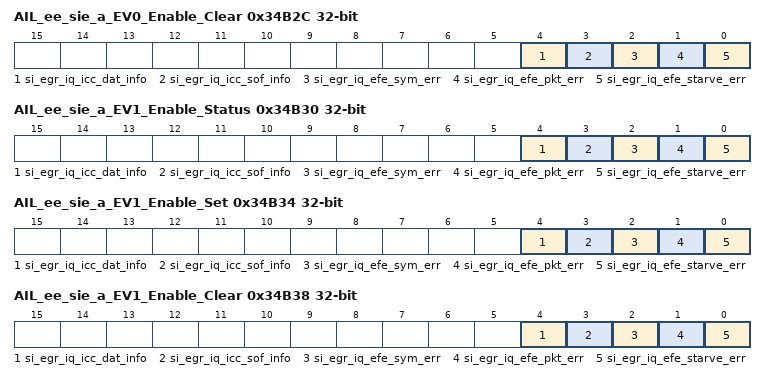
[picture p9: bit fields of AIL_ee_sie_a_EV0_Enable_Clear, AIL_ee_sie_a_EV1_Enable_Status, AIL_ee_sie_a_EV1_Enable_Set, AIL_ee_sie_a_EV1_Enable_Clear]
0x34B2C AIL_ee_sie_a_EV0_Enable_Clear wo — (1 of 1, stride 0)
  [4] si_egr_iq_icc_dat_info — Clears the corresponding bit in the enable register when set. Write only, self-clears.
  [3] si_egr_iq_icc_sof_info — Clears the corresponding bit in the enable register when set. Write only, self-clears.
  [2] si_egr_iq_efe_sym_err — Clears the corresponding bit in the enable register when set. Write only, self-clears.
  [1] si_egr_iq_efe_pkt_err — Clears the corresponding bit in the enable register when set. Write only, self-clears.
  [0] si_egr_iq_efe_starve_err — Clears the corresponding bit in the enable register when set. Write only, self-clears.
0x34B30 AIL_ee_sie_a_EV1_Enable_Status — (1 of 1, stride 0)
  [4] si_egr_iq_icc_dat_info — When set allows the corresponding bit in the raw_status register to generate the intr1_sts interrupt. Read only.
  [3] si_egr_iq_icc_sof_info — When set allows the corresponding bit in the raw_status register to generate the intr1_sts interrupt. Read only.
  [2] si_egr_iq_efe_sym_err — When set allows the corresponding bit in the raw_status register to generate the intr1_sts interrupt. Read only.
  [1] si_egr_iq_efe_pkt_err — When set allows the corresponding bit in the raw_status register to generate the intr1_sts interrupt. Read only.
  [0] si_egr_iq_efe_starve_err — When set allows the corresponding bit in the raw_status register to generate the intr1_sts interrupt. Read only.
0x34B34 AIL_ee_sie_a_EV1_Enable_Set wo — (1 of 1, stride 0)
  [4] si_egr_iq_icc_dat_info — Sets the corresponding bit in the intr1_status register when set. Write only, self-clears.
  [3] si_egr_iq_icc_sof_info — Sets the corresponding bit in the intr1_status register when set. Write only, self-clears.
  [2] si_egr_iq_efe_sym_err — Sets the corresponding bit in the intr1_status register when set. Write only, self-clears.
  [1] si_egr_iq_efe_pkt_err — Sets the corresponding bit in the intr1_status register when set. Write only, self-clears.
  [0] si_egr_iq_efe_starve_err — Sets the corresponding bit in the intr1_status register when set. Write only, self-clears.
0x34B38 AIL_ee_sie_a_EV1_Enable_Clear wo — (1 of 1, stride 0)
  [4] si_egr_iq_icc_dat_info — Clears the corresponding bit in the intr1_status register when set. Write only, self-clears.
  [3] si_egr_iq_icc_sof_info — Clears the corresponding bit in the intr1_status register when set. Write only, self-clears.
  [2] si_egr_iq_efe_sym_err — Clears the corresponding bit in the intr1_status register when set. Write only, self-clears.
  [1] si_egr_iq_efe_pkt_err — Clears the corresponding bit in the intr1_status register when set. Write only, self-clears.
  [0] si_egr_iq_efe_starve_err — Clears the corresponding bit in the intr1_status register when set. Write only, self-clears.
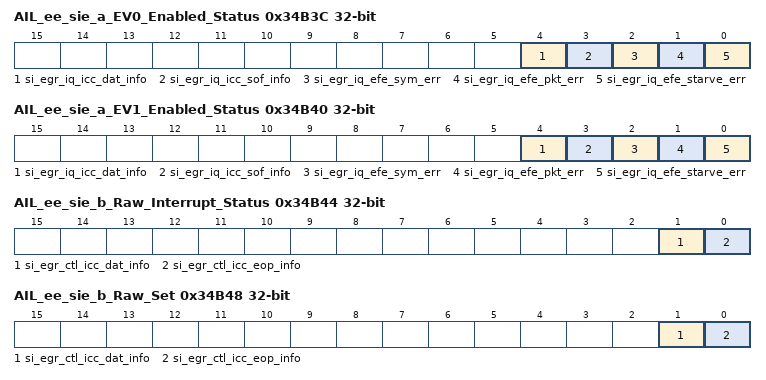
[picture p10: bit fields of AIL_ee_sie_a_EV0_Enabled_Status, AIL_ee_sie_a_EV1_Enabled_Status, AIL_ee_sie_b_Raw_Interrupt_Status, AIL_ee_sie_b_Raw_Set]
0x34B3C AIL_ee_sie_a_EV0_Enabled_Status — (1 of 1, stride 0)
  [4] si_egr_iq_icc_dat_info — AND-ed raw_status bits with the corresponding bit in the enable_status register. Read only.
  [3] si_egr_iq_icc_sof_info — AND-ed raw_status bits with the corresponding bit in the enable_status register. Read only.
  [2] si_egr_iq_efe_sym_err — AND-ed raw_status bits with the corresponding bit in the enable_status register. Read only.
  [1] si_egr_iq_efe_pkt_err — AND-ed raw_status bits with the corresponding bit in the enable_status register. Read only.
  [0] si_egr_iq_efe_starve_err — AND-ed raw_status bits with the corresponding bit in the enable_status register. Read only.
0x34B40 AIL_ee_sie_a_EV1_Enabled_Status — (1 of 1, stride 0)
  [4] si_egr_iq_icc_dat_info — AND-ed raw_status bits with the corresponding bit in the intr1_status register. Read only.
  [3] si_egr_iq_icc_sof_info — AND-ed raw_status bits with the corresponding bit in the intr1_status register. Read only.
  [2] si_egr_iq_efe_sym_err — AND-ed raw_status bits with the corresponding bit in the intr1_status register. Read only.
  [1] si_egr_iq_efe_pkt_err — AND-ed raw_status bits with the corresponding bit in the intr1_status register. Read only.
  [0] si_egr_iq_efe_starve_err — AND-ed raw_status bits with the corresponding bit in the intr1_status register. Read only.
0x34B44 AIL_ee_sie_b_Raw_Interrupt_Status — (1 of 1, stride 0)
  [1] si_egr_ctl_icc_dat_info — SI Egress CTL transmitted data to ICC
  [0] si_egr_ctl_icc_eop_info — SI Egress CTL transmitted EOP to ICC
0x34B48 AIL_ee_sie_b_Raw_Set wo — (1 of 1, stride 0)
  [1] si_egr_ctl_icc_dat_info — Sets the corresponding bit in the raw_status register when set. Write only, self-clears.
  [0] si_egr_ctl_icc_eop_info — Sets the corresponding bit in the raw_status register when set. Write only, self-clears.
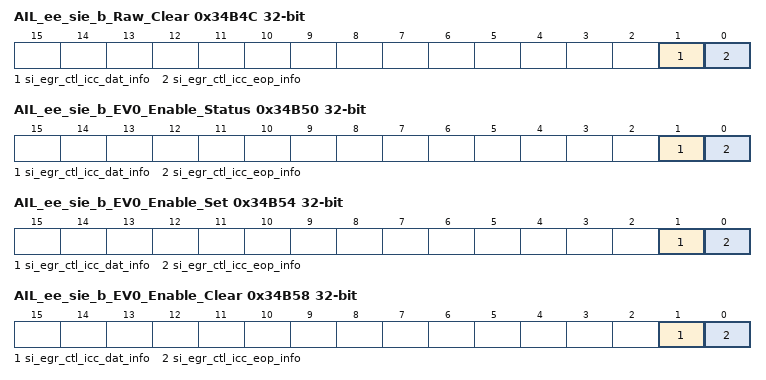
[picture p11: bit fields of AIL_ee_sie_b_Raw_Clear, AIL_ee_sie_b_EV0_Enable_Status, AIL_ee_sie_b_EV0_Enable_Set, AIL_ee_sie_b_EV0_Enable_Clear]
0x34B4C AIL_ee_sie_b_Raw_Clear wo — (1 of 1, stride 0)
  [1] si_egr_ctl_icc_dat_info — Clears the corresponding bit in the raw_status register when set. Write only, self-clears.
  [0] si_egr_ctl_icc_eop_info — Clears the corresponding bit in the raw_status register when set. Write only, self-clears.
0x34B50 AIL_ee_sie_b_EV0_Enable_Status — (1 of 1, stride 0)
  [1] si_egr_ctl_icc_dat_info — When set allows the corresponding bit in the raw_status register to generate the intr_sts interrupt. Read only.
  [0] si_egr_ctl_icc_eop_info — When set allows the corresponding bit in the raw_status register to generate the intr_sts interrupt. Read only.
0x34B54 AIL_ee_sie_b_EV0_Enable_Set wo — (1 of 1, stride 0)
  [1] si_egr_ctl_icc_dat_info — Sets the corresponding bit in the enable register when set. Write only, self-clears.
  [0] si_egr_ctl_icc_eop_info — Sets the corresponding bit in the enable register when set. Write only, self-clears.
0x34B58 AIL_ee_sie_b_EV0_Enable_Clear wo — (1 of 1, stride 0)
  [1] si_egr_ctl_icc_dat_info — Clears the corresponding bit in the enable register when set. Write only, self-clears.
  [0] si_egr_ctl_icc_eop_info — Clears the corresponding bit in the enable register when set. Write only, self-clears.
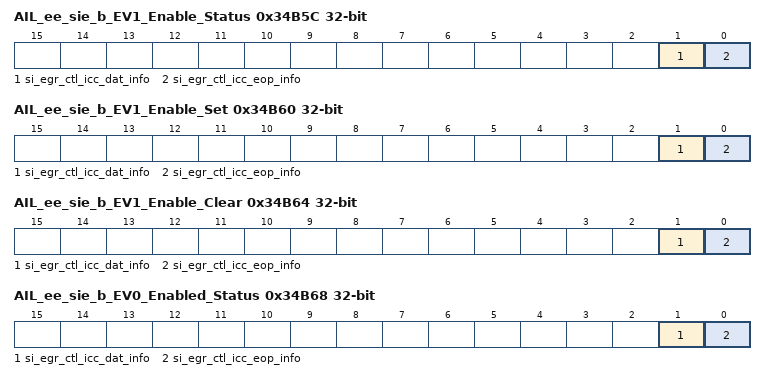
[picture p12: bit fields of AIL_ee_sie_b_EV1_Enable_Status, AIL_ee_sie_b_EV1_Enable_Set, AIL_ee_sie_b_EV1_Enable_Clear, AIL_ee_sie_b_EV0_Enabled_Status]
0x34B5C AIL_ee_sie_b_EV1_Enable_Status — (1 of 1, stride 0)
  [1] si_egr_ctl_icc_dat_info — When set allows the corresponding bit in the raw_status register to generate the intr1_sts interrupt. Read only.
  [0] si_egr_ctl_icc_eop_info — When set allows the corresponding bit in the raw_status register to generate the intr1_sts interrupt. Read only.
0x34B60 AIL_ee_sie_b_EV1_Enable_Set wo — (1 of 1, stride 0)
  [1] si_egr_ctl_icc_dat_info — Sets the corresponding bit in the intr1_status register when set. Write only, self-clears.
  [0] si_egr_ctl_icc_eop_info — Sets the corresponding bit in the intr1_status register when set. Write only, self-clears.
0x34B64 AIL_ee_sie_b_EV1_Enable_Clear wo — (1 of 1, stride 0)
  [1] si_egr_ctl_icc_dat_info — Clears the corresponding bit in the intr1_status register when set. Write only, self-clears.
  [0] si_egr_ctl_icc_eop_info — Clears the corresponding bit in the intr1_status register when set. Write only, self-clears.
0x34B68 AIL_ee_sie_b_EV0_Enabled_Status — (1 of 1, stride 0)
  [1] si_egr_ctl_icc_dat_info — AND-ed raw_status bits with the corresponding bit in the enable_status register. Read only.
  [0] si_egr_ctl_icc_eop_info — AND-ed raw_status bits with the corresponding bit in the enable_status register. Read only.
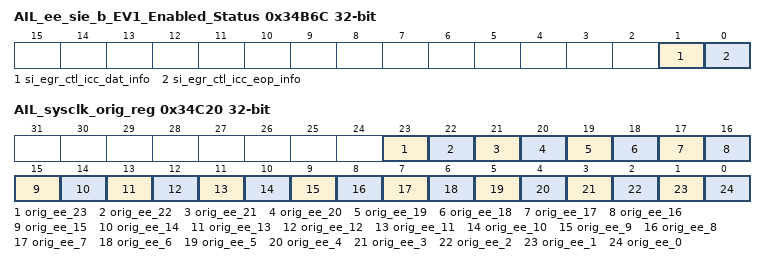
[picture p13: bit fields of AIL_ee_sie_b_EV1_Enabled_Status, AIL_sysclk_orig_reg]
0x34B6C AIL_ee_sie_b_EV1_Enabled_Status — (1 of 1, stride 0)
  [1] si_egr_ctl_icc_dat_info — AND-ed raw_status bits with the corresponding bit in the intr1_status register. Read only.
  [0] si_egr_ctl_icc_eop_info — AND-ed raw_status bits with the corresponding bit in the intr1_status register. Read only.
0x34B70 AIL_ee_sie_c_Raw_Interrupt_Status — (1 of 1, stride 0)
  [3:0] si_egr_ctl_icc_sop_info — SI Egress CTL per channel SOP transmitted to ICC
0x34B74 AIL_ee_sie_c_Raw_Set wo — (1 of 1, stride 0)
  [3:0] si_egr_ctl_icc_sop_info — Sets the corresponding bit in the raw_status register when set. Write only, self-clears.
0x34B78 AIL_ee_sie_c_Raw_Clear wo — (1 of 1, stride 0)
  [3:0] si_egr_ctl_icc_sop_info — Clears the corresponding bit in the raw_status register when set. Write only, self-clears.
0x34B7C AIL_ee_sie_c_EV0_Enable_Status — (1 of 1, stride 0)
  [3:0] si_egr_ctl_icc_sop_info — When set allows the corresponding bit in the raw_status register to generate the intr_sts interrupt. Read only.
0x34B80 AIL_ee_sie_c_EV0_Enable_Set wo — (1 of 1, stride 0)
  [3:0] si_egr_ctl_icc_sop_info — Sets the corresponding bit in the enable register when set. Write only, self-clears.
0x34B84 AIL_ee_sie_c_EV0_Enable_Clear wo — (1 of 1, stride 0)
  [3:0] si_egr_ctl_icc_sop_info — Clears the corresponding bit in the enable register when set. Write only, self-clears.
0x34B88 AIL_ee_sie_c_EV1_Enable_Status — (1 of 1, stride 0)
  [3:0] si_egr_ctl_icc_sop_info — When set allows the corresponding bit in the raw_status register to generate the intr1_sts interrupt. Read only.
0x34B8C AIL_ee_sie_c_EV1_Enable_Set wo — (1 of 1, stride 0)
  [3:0] si_egr_ctl_icc_sop_info — Sets the corresponding bit in the intr1_status register when set. Write only, self-clears.
0x34B90 AIL_ee_sie_c_EV1_Enable_Clear wo — (1 of 1, stride 0)
  [3:0] si_egr_ctl_icc_sop_info — Clears the corresponding bit in the intr1_status register when set. Write only, self-clears.
0x34B94 AIL_ee_sie_c_EV0_Enabled_Status — (1 of 1, stride 0)
  [3:0] si_egr_ctl_icc_sop_info — AND-ed raw_status bits with the corresponding bit in the enable_status register. Read only.
0x34B98 AIL_ee_sie_c_EV1_Enabled_Status — (1 of 1, stride 0)
  [3:0] si_egr_ctl_icc_sop_info — AND-ed raw_status bits with the corresponding bit in the intr1_status register. Read only.
0x34C20 AIL_sysclk_orig_reg — (1 of 1, stride 0)
  [23] orig_ee_23 — Reserved.
  [22] orig_ee_22 — Reserved.
  [21] orig_ee_21 — Reserved.
  [20] orig_ee_20 — If set a bit is set in the ee_sie_c register.
  [19] orig_ee_19 — If set a bit is set in the ee_sie_b register.
  [18] orig_ee_18 — If set a bit is set in the ee_sie_a register.
  [17] orig_ee_17 — Reserved.
  [16] orig_ee_16 — Reserved.
  [15] orig_ee_15 — Reserved.
  [14] orig_ee_14 — If set a bit is set in the ee_sii_d register.
  [13] orig_ee_13 — Reserved.
  [12] orig_ee_12 — Reserved.
  [11] orig_ee_11 — If set a bit is set in the ee_sii_c_1 register.
  [10] orig_ee_10 — If set a bit is set in the ee_sii_c_0 register.
  [9] orig_ee_9 — If set a bit is set in the ee_sii_b register.
  [8] orig_ee_8 — If set a bit is set in the ee_sii_a register.
  [7] orig_ee_7 — If set a bit is set in the uat_0 register.
  [6] orig_ee_6 — If set a bit is set in the pe_0 register.
  [5] orig_ee_5 — Reserved.
  [4] orig_ee_4 — Reserved.
  [3] orig_ee_3 — If set a bit is set in the pd_2_1 register.
  [2] orig_ee_2 — If set a bit is set in the pd_2_0 register.
  [1] orig_ee_1 — If set a bit is set in the pd_1 register.
  [0] orig_ee_0 — If set a bit is set in the pd_0 register.
